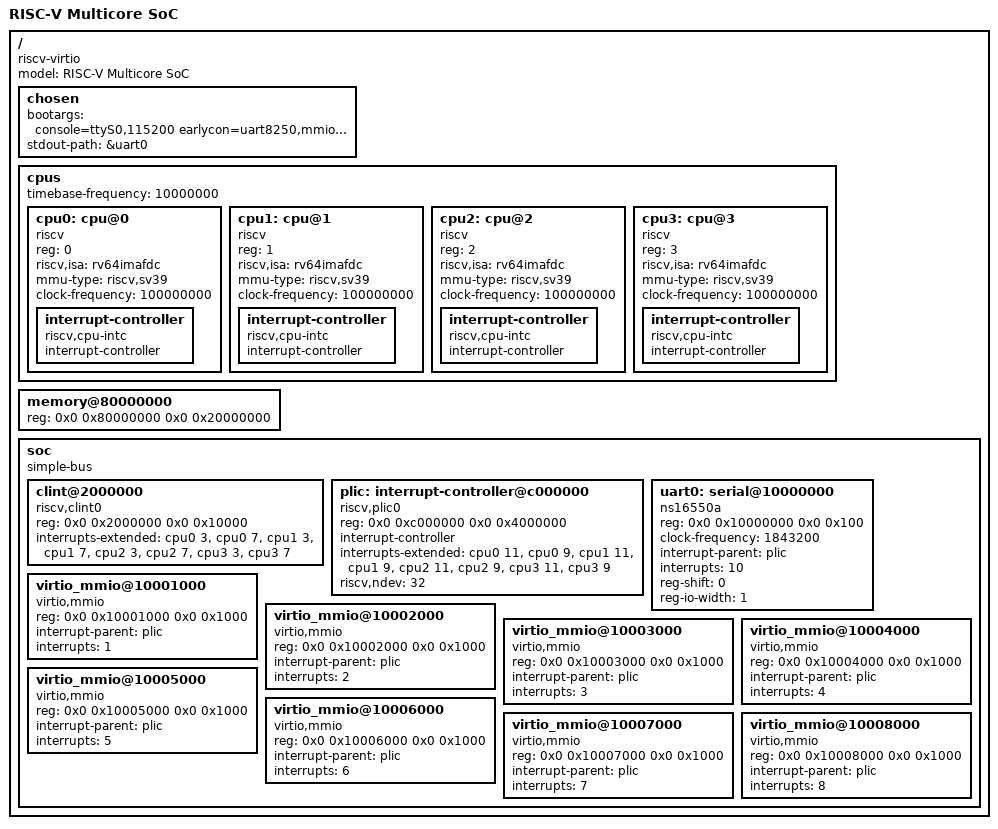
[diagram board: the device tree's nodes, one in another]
/dts-v1/;

/ {
    #address-cells = <2>;
    #size-cells = <2>;
    compatible = "riscv-virtio";
    model = "RISC-V Multicore SoC";

    chosen {
        bootargs = "console=ttyS0,115200 earlycon=uart8250,mmio,0x10000000 root=/dev/ram0 rw";
        stdout-path = &uart0;
    };

    cpus {
        #address-cells = <1>;
        #size-cells = <0>;
        timebase-frequency = <10000000>; // 10MHz timebase
        
        cpu0: cpu@0 {
            device_type = "cpu";
            reg = <0>;
            status = "okay";
            compatible = "riscv";
            riscv,isa = "rv64imafdc";
            mmu-type = "riscv,sv39";
            clock-frequency = <100000000>; // 100MHz
            
            interrupt-controller {
                #interrupt-cells = <1>;
                interrupt-controller;
                compatible = "riscv,cpu-intc";
            };
        };
        
        cpu1: cpu@1 {
            device_type = "cpu";
            reg = <1>;
            status = "okay";
            compatible = "riscv";
            riscv,isa = "rv64imafdc";
            mmu-type = "riscv,sv39";
            clock-frequency = <100000000>;
            
            interrupt-controller {
                #interrupt-cells = <1>;
                interrupt-controller;
                compatible = "riscv,cpu-intc";
            };
        };
        
        cpu2: cpu@2 {
            device_type = "cpu";
            reg = <2>;
            status = "okay";
            compatible = "riscv";
            riscv,isa = "rv64imafdc";
            mmu-type = "riscv,sv39";
            clock-frequency = <100000000>;
            
            interrupt-controller {
                #interrupt-cells = <1>;
                interrupt-controller;
                compatible = "riscv,cpu-intc";
            };
        };
        
        cpu3: cpu@3 {
            device_type = "cpu";
            reg = <3>;
            status = "okay";
            compatible = "riscv";
            riscv,isa = "rv64imafdc";
            mmu-type = "riscv,sv39";
            clock-frequency = <100000000>;
            
            interrupt-controller {
                #interrupt-cells = <1>;
                interrupt-controller;
                compatible = "riscv,cpu-intc";
            };
        };
    };

    memory@80000000 {
        device_type = "memory";
        reg = <0x0 0x80000000 0x0 0x20000000>; // 512MB at 0x80000000
    };

    soc {
        #address-cells = <2>;
        #size-cells = <2>;
        compatible = "simple-bus";
        ranges;

        // Core Local Interruptor (CLINT)
        clint@2000000 {
            compatible = "riscv,clint0";
            reg = <0x0 0x2000000 0x0 0x10000>;
            interrupts-extended = <&cpu0 3>, <&cpu0 7>,
                                  <&cpu1 3>, <&cpu1 7>,
                                  <&cpu2 3>, <&cpu2 7>,
                                  <&cpu3 3>, <&cpu3 7>;
        };

        // Platform Level Interrupt Controller (PLIC)
        plic: interrupt-controller@c000000 {
            compatible = "riscv,plic0";
            reg = <0x0 0xc000000 0x0 0x4000000>;
            #interrupt-cells = <1>;
            interrupt-controller;
            interrupts-extended = <&cpu0 11>, <&cpu0 9>,
                                  <&cpu1 11>, <&cpu1 9>,
                                  <&cpu2 11>, <&cpu2 9>,
                                  <&cpu3 11>, <&cpu3 9>;
            riscv,ndev = <32>;
        };

        // UART
        uart0: serial@10000000 {
            compatible = "ns16550a";
            reg = <0x0 0x10000000 0x0 0x100>;
            clock-frequency = <1843200>;
            interrupt-parent = <&plic>;
            interrupts = <10>;
            reg-shift = <0>;
            reg-io-width = <1>;
        };

        // Virtio MMIO devices
        virtio_mmio@10001000 {
            compatible = "virtio,mmio";
            reg = <0x0 0x10001000 0x0 0x1000>;
            interrupt-parent = <&plic>;
            interrupts = <1>;
        };

        virtio_mmio@10002000 {
            compatible = "virtio,mmio";
            reg = <0x0 0x10002000 0x0 0x1000>;
            interrupt-parent = <&plic>;
            interrupts = <2>;
        };

        virtio_mmio@10003000 {
            compatible = "virtio,mmio";
            reg = <0x0 0x10003000 0x0 0x1000>;
            interrupt-parent = <&plic>;
            interrupts = <3>;
        };

        virtio_mmio@10004000 {
            compatible = "virtio,mmio";
            reg = <0x0 0x10004000 0x0 0x1000>;
            interrupt-parent = <&plic>;
            interrupts = <4>;
        };

        virtio_mmio@10005000 {
            compatible = "virtio,mmio";
            reg = <0x0 0x10005000 0x0 0x1000>;
            interrupt-parent = <&plic>;
            interrupts = <5>;
        };

        virtio_mmio@10006000 {
            compatible = "virtio,mmio";
            reg = <0x0 0x10006000 0x0 0x1000>;
            interrupt-parent = <&plic>;
            interrupts = <6>;
        };

        virtio_mmio@10007000 {
            compatible = "virtio,mmio";
            reg = <0x0 0x10007000 0x0 0x1000>;
            interrupt-parent = <&plic>;
            interrupts = <7>;
        };

        virtio_mmio@10008000 {
            compatible = "virtio,mmio";
            reg = <0x0 0x10008000 0x0 0x1000>;
            interrupt-parent = <&plic>;
            interrupts = <8>;
        };
    };
}; 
